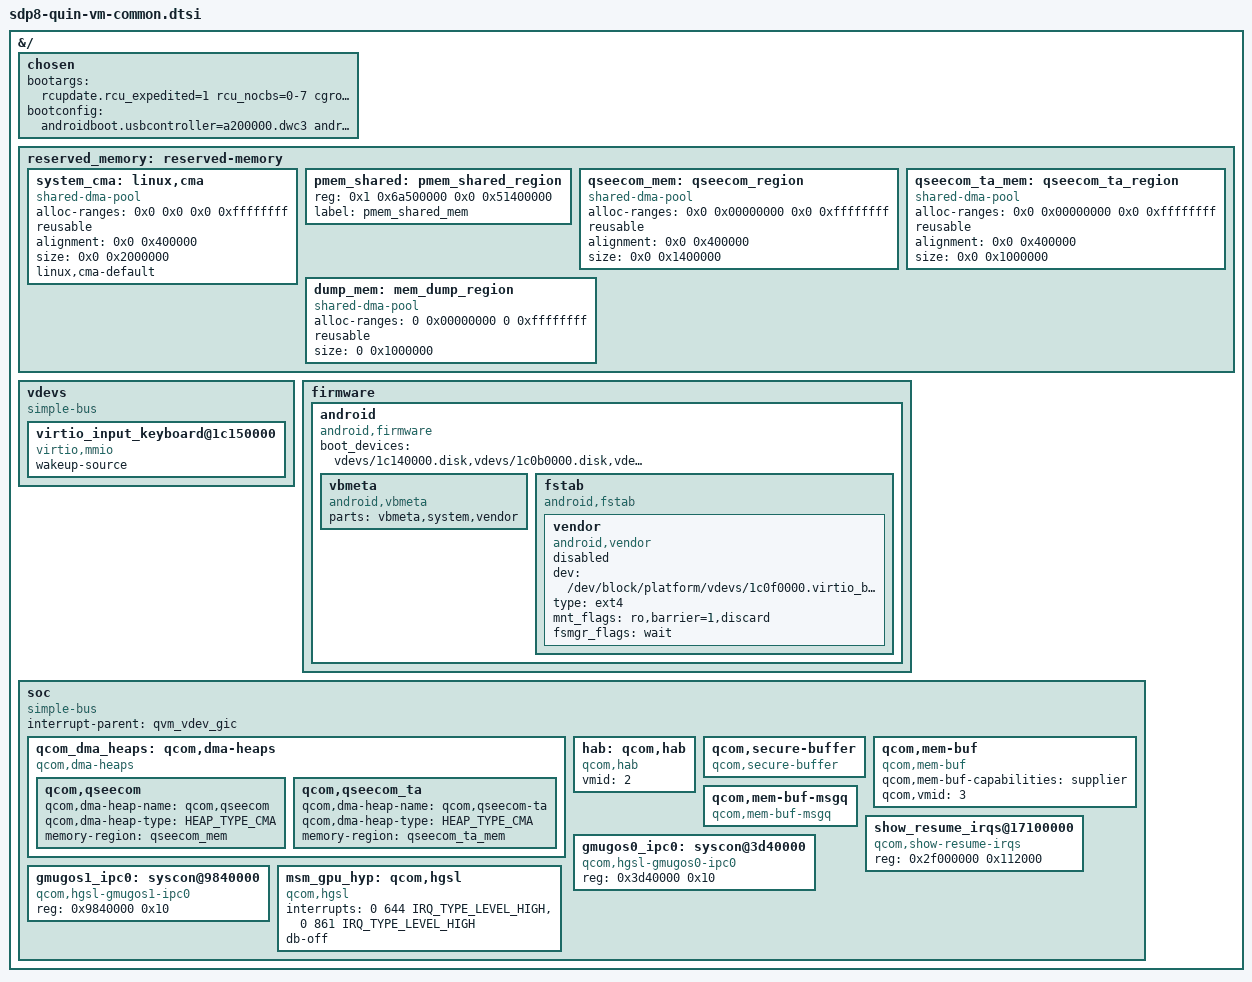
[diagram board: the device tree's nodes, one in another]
#include <dt-bindings/interrupt-controller/arm-gic.h>
#include <dt-bindings/gpio/gpio.h>
#include <dt-bindings/arm/msm/qcom_dma_heap_dt_constants.h>
#include <dt-bindings/clock/qcom,rpmh.h>
#include <dt-bindings/regulator/qcom,rpmh-regulator-levels.h>

&{/} {
	chosen: chosen {
		bootargs = "rcupdate.rcu_expedited=1 rcu_nocbs=0-7 cgroup.memory=nokmem,nosocket kpti=0 ufshcd-core.use_mcq_mode=n qcom_dma_heaps.enable_bitstream_contig_heap=y arm64.nopauth kasan=off msm_show_resume_irq.debug_mask=1 fw_devlink.strict=1";
		bootconfig = "androidboot.usbcontroller=a200000.dwc3 androidboot.dtbo_idx=4";
	};

	reserved_memory: reserved-memory {
		#address-cells = <2>;
		#size-cells = <2>;
		ranges;

		system_cma: linux,cma {
			compatible = "shared-dma-pool";
			alloc-ranges = <0x0 0x0 0x0 0xffffffff>;
			reusable;
			alignment = <0x0 0x400000>;
			size = <0x0 0x2000000>;
			linux,cma-default;
		};

		pmem_shared: pmem_shared_region {
			reg = <0x1 0x6a500000 0x0 0x51400000>;
			label = "pmem_shared_mem";
		};

		qseecom_mem: qseecom_region {
			compatible = "shared-dma-pool";
			alloc-ranges = <0x0 0x00000000 0x0 0xffffffff>;
			reusable;
			alignment = <0x0 0x400000>;
			size = <0x0 0x1400000>;
		};

		qseecom_ta_mem: qseecom_ta_region {
			compatible = "shared-dma-pool";
			alloc-ranges = <0x0 0x00000000 0x0 0xffffffff>;
			reusable;
			alignment = <0x0 0x400000>;
			size = <0x0 0x1000000>;
		};

		dump_mem: mem_dump_region {
			compatible = "shared-dma-pool";
			alloc-ranges = <0 0x00000000 0 0xffffffff>;
			reusable;
			size = <0 0x1000000>;
		};
	};

	vdevs {
		compatible = "simple-bus";
		virtio_input_keyboard@1c150000 {
			compatible = "virtio,mmio";
			wakeup-source;
		};
	};

	firmware: firmware {
		android {
			compatible = "android,firmware";
			boot_devices = "vdevs/1c140000.disk,vdevs/1c0b0000.disk,vdevs/1c0f0000.disk,vdevs/1c410000.disk,vdevs/1c130000.disk,vdevs/1c0e0000.disk,vdevs/1c100000.disk,vdevs/1c170000.disk,vdevs/1c180000.disk,vdevs/1c110000.disk,vdevs/1c120000.disk,vdevs/1c210000.disk,vdevs/1c220000.disk,vdevs/1c230000.disk,vdevs/1c240000.disk,vdevs/1c250000.disk,vdevs/1c260000.disk,vdevs/1c280000.disk,vdevs/1c290000.disk,vdevs/1c310000.disk,vdevs/1c320000.disk";

			vbmeta {
				compatible = "android,vbmeta";
				parts = "vbmeta,system,vendor";
			};

			fstab {
				compatible = "android,fstab";
				vendor {
					compatible = "android,vendor";
					dev="/dev/block/platform/vdevs/1c0f0000.virtio_blk/vdc";
					type = "ext4";
					mnt_flags = "ro,barrier=1,discard";
					fsmgr_flags = "wait";
					status = "disabled";
				};
			};
		};
	};

	soc: soc {
		#address-cells = <1>;
		#size-cells = <1>;
		interrupt-parent = <&qvm_vdev_gic>;
		ranges = <0x0 0x0 0x0 0xffffffff>;
		compatible = "simple-bus";

		qcom_dma_heaps: qcom,dma-heaps {
			compatible = "qcom,dma-heaps";

			qcom,qseecom {
				qcom,dma-heap-name = "qcom,qseecom";
				qcom,dma-heap-type = <HEAP_TYPE_CMA>;
				memory-region = <&qseecom_mem>;
			};

			qcom,qseecom_ta {
				qcom,dma-heap-name = "qcom,qseecom-ta";
				qcom,dma-heap-type = <HEAP_TYPE_CMA>;
				memory-region = <&qseecom_ta_mem>;
			};
		};

		hab: qcom,hab {
			compatible = "qcom,hab";
			vmid = <2>;
		};

		qcom,secure-buffer {
			compatible = "qcom,secure-buffer";
		};

		qcom,mem-buf {
			compatible = "qcom,mem-buf";
			qcom,mem-buf-capabilities = "supplier";
			qcom,vmid = <3>;
		};

		qcom,mem-buf-msgq {
			compatible = "qcom,mem-buf-msgq";
		};

		show_resume_irqs@17100000 {
			compatible = "qcom,show-resume-irqs";
			reg = <0x2f000000 0x112000>;
		};

		gmugos0_ipc0: syscon@3d40000 {
			compatible = "qcom,hgsl-gmugos0-ipc0", "syscon";
			reg = <0x3d40000 0x10>;
		};

		gmugos1_ipc0: syscon@9840000 {
			compatible = "qcom,hgsl-gmugos1-ipc0", "syscon";
			reg = <0x9840000 0x10>;
		};

		msm_gpu_hyp: qcom,hgsl {
			compatible = "qcom,hgsl";

			interrupts = <0 644 IRQ_TYPE_LEVEL_HIGH>,
				/* gmugos1 */
				<0 861 IRQ_TYPE_LEVEL_HIGH>;

			interrupt-names = "hgsl_gmugos0_irq0",
				/* gmugos1 */
				"hgsl_gmugos1_irq0";

			db-off;
		};
	};
};
